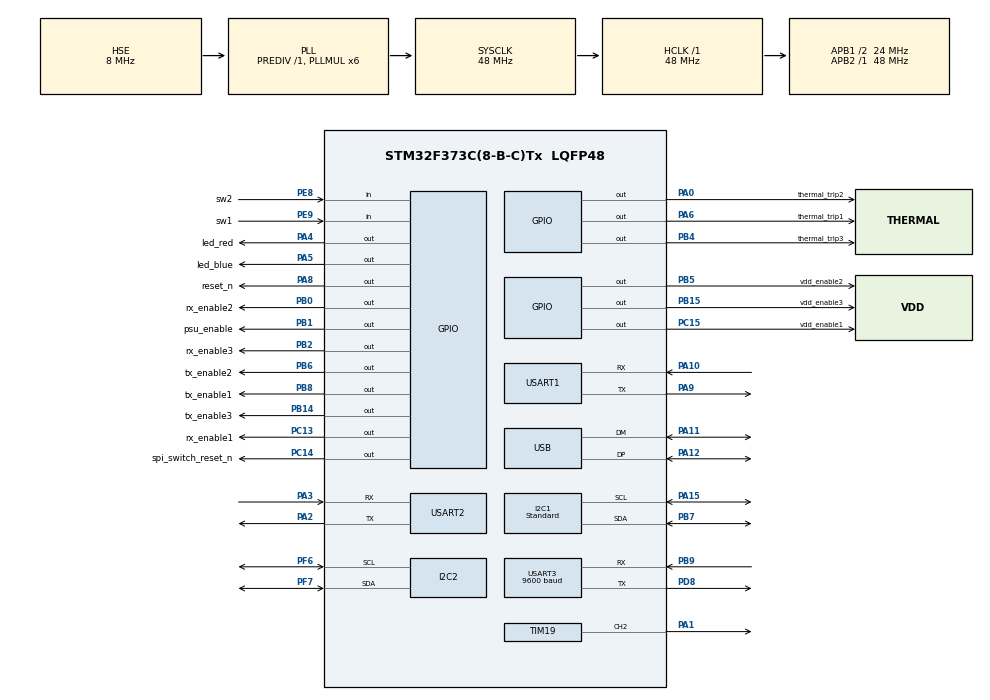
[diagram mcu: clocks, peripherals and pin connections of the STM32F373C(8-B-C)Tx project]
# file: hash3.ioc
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Dma.Request0=USART1_RX
Dma.Request1=USART1_TX
Dma.Request2=USART2_RX
Dma.Request3=USART2_TX
Dma.Request4=USART3_RX
Dma.Request5=USART3_TX
Dma.USART1_RX.0.Direction=DMA_PERIPH_TO_MEMORY
Dma.USART1_RX.0.Instance=DMA1_Channel5
Dma.USART1_RX.0.MemDataAlignment=DMA_MDATAALIGN_BYTE
Dma.USART1_RX.0.MemInc=DMA_MINC_ENABLE
Dma.USART1_RX.0.Mode=DMA_CIRCULAR
Dma.USART1_RX.0.PeriphDataAlignment=DMA_PDATAALIGN_BYTE
Dma.USART1_RX.0.PeriphInc=DMA_PINC_DISABLE
Dma.USART1_RX.0.Priority=DMA_PRIORITY_LOW
Dma.USART1_TX.1.Direction=DMA_MEMORY_TO_PERIPH
Dma.USART1_TX.1.Instance=DMA1_Channel4
Dma.USART1_TX.1.MemDataAlignment=DMA_MDATAALIGN_BYTE
Dma.USART1_TX.1.MemInc=DMA_MINC_ENABLE
Dma.USART1_TX.1.Mode=DMA_NORMAL
Dma.USART1_TX.1.PeriphDataAlignment=DMA_PDATAALIGN_BYTE
Dma.USART1_TX.1.PeriphInc=DMA_PINC_DISABLE
Dma.USART1_TX.1.Priority=DMA_PRIORITY_LOW
Dma.USART2_RX.2.Direction=DMA_PERIPH_TO_MEMORY
Dma.USART2_RX.2.Instance=DMA1_Channel6
Dma.USART2_RX.2.MemDataAlignment=DMA_MDATAALIGN_BYTE
Dma.USART2_RX.2.MemInc=DMA_MINC_ENABLE
Dma.USART2_RX.2.Mode=DMA_CIRCULAR
Dma.USART2_RX.2.PeriphDataAlignment=DMA_PDATAALIGN_BYTE
Dma.USART2_RX.2.PeriphInc=DMA_PINC_DISABLE
Dma.USART2_RX.2.Priority=DMA_PRIORITY_LOW
Dma.USART2_TX.3.Direction=DMA_MEMORY_TO_PERIPH
Dma.USART2_TX.3.Instance=DMA1_Channel7
Dma.USART2_TX.3.MemDataAlignment=DMA_MDATAALIGN_BYTE
Dma.USART2_TX.3.MemInc=DMA_MINC_ENABLE
Dma.USART2_TX.3.Mode=DMA_NORMAL
Dma.USART2_TX.3.PeriphDataAlignment=DMA_PDATAALIGN_BYTE
Dma.USART2_TX.3.PeriphInc=DMA_PINC_DISABLE
Dma.USART2_TX.3.Priority=DMA_PRIORITY_LOW
Dma.USART3_RX.4.Direction=DMA_PERIPH_TO_MEMORY
Dma.USART3_RX.4.Instance=DMA1_Channel3
Dma.USART3_RX.4.MemDataAlignment=DMA_MDATAALIGN_BYTE
Dma.USART3_RX.4.MemInc=DMA_MINC_ENABLE
Dma.USART3_RX.4.Mode=DMA_CIRCULAR
Dma.USART3_RX.4.PeriphDataAlignment=DMA_PDATAALIGN_BYTE
Dma.USART3_RX.4.PeriphInc=DMA_PINC_DISABLE
Dma.USART3_RX.4.Priority=DMA_PRIORITY_LOW
Dma.USART3_TX.5.Direction=DMA_MEMORY_TO_PERIPH
Dma.USART3_TX.5.Instance=DMA1_Channel2
Dma.USART3_TX.5.MemDataAlignment=DMA_MDATAALIGN_BYTE
Dma.USART3_TX.5.MemInc=DMA_MINC_ENABLE
Dma.USART3_TX.5.Mode=DMA_NORMAL
Dma.USART3_TX.5.PeriphDataAlignment=DMA_PDATAALIGN_BYTE
Dma.USART3_TX.5.PeriphInc=DMA_PINC_DISABLE
Dma.USART3_TX.5.Priority=DMA_PRIORITY_LOW
I2C1.I2C_Speed_Mode=I2C_Standard
Mcu.Family=STM32F3
Mcu.Name=STM32F373C(8-B-C)Tx
Mcu.Package=LQFP48
NVIC.DMA1_Channel2_IRQn=true\:0\:0\:false\:false\:true\:false\:true\:true
NVIC.DMA1_Channel3_IRQn=true\:0\:0\:false\:false\:true\:false\:true\:true
NVIC.DMA1_Channel4_IRQn=true\:0\:0\:false\:false\:true\:false\:true\:true
NVIC.DMA1_Channel5_IRQn=true\:0\:0\:false\:false\:true\:false\:true\:true
NVIC.DMA1_Channel6_IRQn=true\:0\:0\:false\:false\:true\:false\:true\:true
NVIC.DMA1_Channel7_IRQn=true\:0\:0\:false\:false\:true\:false\:true\:true
NVIC.PriorityGroup=NVIC_PRIORITYGROUP_4
NVIC.USART1_IRQn=true\:0\:0\:false\:false\:true\:true\:true\:true
NVIC.USART2_IRQn=true\:0\:0\:false\:false\:true\:true\:true\:true
NVIC.USART3_IRQn=true\:0\:0\:false\:false\:true\:true\:true\:true
NVIC.USB_LP_IRQn=true\:0\:0\:false\:false\:true\:false\:true\:true
PA0.GPIO_Label=thermal_trip2
PA0.Signal=GPIO_Output
PA1.Signal=S_TIM19_CH2
PA10.Mode=Asynchronous
PA10.Signal=USART1_RX
PA11.Mode=Device
PA11.Signal=USB_DM
PA12.Mode=Device
PA12.Signal=USB_DP
PA13.Mode=Trace_Asynchronous_SW
PA13.Signal=SYS_JTMS-SWDIO
PA14.Mode=Trace_Asynchronous_SW
PA14.Signal=SYS_JTCK-SWCLK
PA15.Mode=I2C
PA15.Signal=I2C1_SCL
PA2.Mode=Asynchronous
PA2.Signal=USART2_TX
PA3.Mode=Asynchronous
PA3.Signal=USART2_RX
PA4.GPIO_Label=led_red
PA4.Signal=GPIO_Output
PA5.GPIO_Label=led_blue
PA5.Signal=GPIO_Output
PA6.GPIO_Label=thermal_trip1
PA6.Signal=GPIO_Output
PA8.GPIO_Label=reset_n
PA8.Signal=GPIO_Output
PA9.Mode=Asynchronous
PA9.Signal=USART1_TX
PB0.GPIO_Label=rx_enable2
PB0.Signal=GPIO_Output
PB1.GPIO_Label=psu_enable
PB1.Signal=GPIO_Output
PB14.GPIO_Label=tx_enable3
PB14.Signal=GPIO_Output
PB15.GPIO_Label=vdd_enable3
PB15.Signal=GPIO_Output
PB2.GPIO_Label=rx_enable3
PB2.Signal=GPIO_Output
PB3.Mode=Trace_Asynchronous_SW
PB3.Signal=SYS_JTDO-TRACESWO
PB4.GPIO_Label=thermal_trip3
PB4.Signal=GPIO_Output
PB5.GPIO_Label=vdd_enable2
PB5.Signal=GPIO_Output
PB6.GPIO_Label=tx_enable2
PB6.Signal=GPIO_Output
PB7.Mode=I2C
PB7.Signal=I2C1_SDA
PB8.GPIO_Label=tx_enable1
PB8.Signal=GPIO_Output
PB9.Mode=Asynchronous
PB9.Signal=USART3_RX
PC13.GPIO_Label=rx_enable1
PC13.Signal=GPIO_Output
PC14-OSC32_IN.GPIO_Label=spi_switch_reset_n
PC14-OSC32_IN.Signal=GPIO_Output
PC15-OSC32_OUT.GPIO_Label=vdd_enable1
PC15-OSC32_OUT.Signal=GPIO_Output
PD8.Mode=Asynchronous
PD8.Signal=USART3_TX
PE8.GPIO_Label=sw2
PE8.GPIO_PuPd=GPIO_PULLUP
PE8.Signal=GPIO_Input
PE9.GPIO_Label=sw1
PE9.GPIO_PuPd=GPIO_PULLUP
PE9.Signal=GPIO_Input
PF0-OSC_IN.Mode=HSE-External-Oscillator
PF0-OSC_IN.Signal=RCC_OSC_IN
PF1-OSC_OUT.Mode=HSE-External-Oscillator
PF1-OSC_OUT.Signal=RCC_OSC_OUT
PF6.Mode=I2C
PF6.Signal=I2C2_SCL
PF7.Mode=I2C
PF7.Signal=I2C2_SDA
ProjectManager.HeapSize=0x800
ProjectManager.StackSize=0x800
ProjectManager.TargetToolchain=STM32CubeIDE
RCC.AHBFreq_Value=48000000
RCC.APB1CLKDivider=RCC_HCLK_DIV2
RCC.APB1Freq_Value=24000000
RCC.APB1TimFreq_Value=48000000
RCC.APB2Freq_Value=48000000
RCC.APB2TimFreq_Value=48000000
RCC.CortexFreq_Value=6000000
RCC.Cortex_Div=SYSTICK_CLKSOURCE_HCLK_DIV8
RCC.HCLKFreq_Value=48000000
RCC.HSE_VALUE=8000000
RCC.HSI_VALUE=8000000
RCC.LSE_VALUE=32768
RCC.PLLMUL=RCC_PLL_MUL6
RCC.SYSCLKFreq_VALUE=48000000
RCC.SYSCLKSource=RCC_SYSCLKSOURCE_PLLCLK
RCC.USBFreq_Value=48000000
RCC.Usart1ClockSelection=RCC_USART1CLKSOURCE_SYSCLK
RCC.Usart2ClockSelection=RCC_USART2CLKSOURCE_SYSCLK
RCC.Usart3ClockSelection=RCC_USART3CLKSOURCE_SYSCLK
SH.S_TIM19_CH2.0=TIM19_CH2,PWM Generation2 CH2
TIM19.AutoReloadPreload=TIM_AUTORELOAD_PRELOAD_ENABLE
TIM19.Channel-PWM\ Generation2\ CH2=TIM_CHANNEL_2
TIM19.Period=2880
TIM19.Pulse-PWM\ Generation2\ CH2=1
USART1.VirtualMode-Asynchronous=VM_ASYNC
USART2.VirtualMode-Asynchronous=VM_ASYNC
USART3.BaudRate=9600
USART3.VirtualMode-Asynchronous=VM_ASYNC
USB_DEVICE.CLASS_NAME_FS=CDC
USB_DEVICE.VirtualMode=Cdc
USB_DEVICE.VirtualModeFS=Cdc_FS
VP_TIM19_VS_ClockSourceINT.Mode=Internal
VP_USB_DEVICE_VS_USB_DEVICE_CDC_FS.Mode=CDC_FS
board=custom

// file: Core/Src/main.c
/* USER CODE BEGIN Header */
/**
  ******************************************************************************
  * @file           : main.c
  * @brief          : Main program body
  ******************************************************************************
  * @attention
  *
  * Copyright (c) 2023 STMicroelectronics.
  * All rights reserved.
  *
  * This software is licensed under terms that can be found in the LICENSE file
  * in the root directory of this software component.
  * If no LICENSE file comes with this software, it is provided AS-IS.
  *
  ******************************************************************************
  */
/* USER CODE END Header */
#include "main.h"
#include "usb_device.h"

I2C_HandleTypeDef hi2c1;
I2C_HandleTypeDef hi2c2;

TIM_HandleTypeDef htim19;

UART_HandleTypeDef huart1;
UART_HandleTypeDef huart2;
UART_HandleTypeDef huart3;
DMA_HandleTypeDef hdma_usart1_rx;
DMA_HandleTypeDef hdma_usart1_tx;
DMA_HandleTypeDef hdma_usart2_rx;
DMA_HandleTypeDef hdma_usart2_tx;
DMA_HandleTypeDef hdma_usart3_rx;
DMA_HandleTypeDef hdma_usart3_tx;

void SystemClock_Config(void);
static void MX_GPIO_Init(void);
static void MX_DMA_Init(void);
static void MX_USART1_UART_Init(void);
static void MX_USART2_UART_Init(void);
static void MX_USART3_UART_Init(void);
static void MX_I2C1_Init(void);
static void MX_I2C2_Init(void);
static void MX_TIM19_Init(void);

/* USER CODE BEGIN 0 */
void Init();
void Loop();

/* USER CODE END 0 */

int main(void)
{

  /* MCU Configuration--------------------------------------------------------*/

  /* Reset of all peripherals, Initializes the Flash interface and the Systick. */
  HAL_Init();

  /* Configure the system clock */
  SystemClock_Config();

  /* Initialize all configured peripherals */
  MX_GPIO_Init();
  MX_DMA_Init();
  MX_USART1_UART_Init();
  MX_USART2_UART_Init();
  MX_USART3_UART_Init();
  MX_I2C1_Init();
  MX_I2C2_Init();
  MX_USB_DEVICE_Init();
  MX_TIM19_Init();
  /* USER CODE BEGIN 2 */
  Init();

  /* USER CODE END 2 */

  /* Infinite loop */
  while (1)
  {

    /* USER CODE BEGIN 3 */
      Loop();
  }
  /* USER CODE END 3 */
}

void SystemClock_Config(void)
{
  RCC_OscInitTypeDef RCC_OscInitStruct = {0};
  RCC_ClkInitTypeDef RCC_ClkInitStruct = {0};
  RCC_PeriphCLKInitTypeDef PeriphClkInit = {0};

  /** Initializes the RCC Oscillators according to the specified parameters
  * in the RCC_OscInitTypeDef structure.
  */
  RCC_OscInitStruct.OscillatorType = RCC_OSCILLATORTYPE_HSI|RCC_OSCILLATORTYPE_HSE;
  RCC_OscInitStruct.HSEState = RCC_HSE_ON;
  RCC_OscInitStruct.HSEPredivValue = RCC_HSE_PREDIV_DIV1;
  RCC_OscInitStruct.HSIState = RCC_HSI_ON;
  RCC_OscInitStruct.HSICalibrationValue = RCC_HSICALIBRATION_DEFAULT;
  RCC_OscInitStruct.PLL.PLLState = RCC_PLL_ON;
  RCC_OscInitStruct.PLL.PLLSource = RCC_PLLSOURCE_HSE;
  RCC_OscInitStruct.PLL.PLLMUL = RCC_PLL_MUL6;
  if (HAL_RCC_OscConfig(&RCC_OscInitStruct) != HAL_OK)
  {
    Error_Handler();
  }

  /** Initializes the CPU, AHB and APB buses clocks
  */
  RCC_ClkInitStruct.ClockType = RCC_CLOCKTYPE_HCLK|RCC_CLOCKTYPE_SYSCLK
                              |RCC_CLOCKTYPE_PCLK1|RCC_CLOCKTYPE_PCLK2;
  RCC_ClkInitStruct.SYSCLKSource = RCC_SYSCLKSOURCE_PLLCLK;
  RCC_ClkInitStruct.AHBCLKDivider = RCC_SYSCLK_DIV1;
  RCC_ClkInitStruct.APB1CLKDivider = RCC_HCLK_DIV2;
  RCC_ClkInitStruct.APB2CLKDivider = RCC_HCLK_DIV1;

  if (HAL_RCC_ClockConfig(&RCC_ClkInitStruct, FLASH_LATENCY_1) != HAL_OK)
  {
    Error_Handler();
  }
  PeriphClkInit.PeriphClockSelection = RCC_PERIPHCLK_USB|RCC_PERIPHCLK_USART1
                              |RCC_PERIPHCLK_USART2|RCC_PERIPHCLK_USART3
                              |RCC_PERIPHCLK_I2C1|RCC_PERIPHCLK_I2C2;
  PeriphClkInit.Usart1ClockSelection = RCC_USART1CLKSOURCE_SYSCLK;
  PeriphClkInit.Usart2ClockSelection = RCC_USART2CLKSOURCE_SYSCLK;
  PeriphClkInit.Usart3ClockSelection = RCC_USART3CLKSOURCE_SYSCLK;
  PeriphClkInit.I2c1ClockSelection = RCC_I2C1CLKSOURCE_HSI;
  PeriphClkInit.I2c2ClockSelection = RCC_I2C2CLKSOURCE_HSI;
  PeriphClkInit.USBClockSelection = RCC_USBCLKSOURCE_PLL;
  if (HAL_RCCEx_PeriphCLKConfig(&PeriphClkInit) != HAL_OK)
  {
    Error_Handler();
  }
}

static void MX_I2C1_Init(void)
{

  hi2c1.Instance = I2C1;
  hi2c1.Init.Timing = 0x2000090E;
  hi2c1.Init.OwnAddress1 = 0;
  hi2c1.Init.AddressingMode = I2C_ADDRESSINGMODE_7BIT;
  hi2c1.Init.DualAddressMode = I2C_DUALADDRESS_DISABLE;
  hi2c1.Init.OwnAddress2 = 0;
  hi2c1.Init.OwnAddress2Masks = I2C_OA2_NOMASK;
  hi2c1.Init.GeneralCallMode = I2C_GENERALCALL_DISABLE;
  hi2c1.Init.NoStretchMode = I2C_NOSTRETCH_DISABLE;
  if (HAL_I2C_Init(&hi2c1) != HAL_OK)
  {
    Error_Handler();
  }

  /** Configure Analogue filter
  */
  if (HAL_I2CEx_ConfigAnalogFilter(&hi2c1, I2C_ANALOGFILTER_ENABLE) != HAL_OK)
  {
    Error_Handler();
  }

  /** Configure Digital filter
  */
  if (HAL_I2CEx_ConfigDigitalFilter(&hi2c1, 0) != HAL_OK)
  {
    Error_Handler();
  }

}

static void MX_I2C2_Init(void)
{

  hi2c2.Instance = I2C2;
  hi2c2.Init.Timing = 0x2000090E;
  hi2c2.Init.OwnAddress1 = 0;
  hi2c2.Init.AddressingMode = I2C_ADDRESSINGMODE_7BIT;
  hi2c2.Init.DualAddressMode = I2C_DUALADDRESS_DISABLE;
  hi2c2.Init.OwnAddress2 = 0;
  hi2c2.Init.OwnAddress2Masks = I2C_OA2_NOMASK;
  hi2c2.Init.GeneralCallMode = I2C_GENERALCALL_DISABLE;
  hi2c2.Init.NoStretchMode = I2C_NOSTRETCH_DISABLE;
  if (HAL_I2C_Init(&hi2c2) != HAL_OK)
  {
    Error_Handler();
  }

  /** Configure Analogue filter
  */
  if (HAL_I2CEx_ConfigAnalogFilter(&hi2c2, I2C_ANALOGFILTER_ENABLE) != HAL_OK)
  {
    Error_Handler();
  }

  /** Configure Digital filter
  */
  if (HAL_I2CEx_ConfigDigitalFilter(&hi2c2, 0) != HAL_OK)
  {
    Error_Handler();
  }

}

static void MX_TIM19_Init(void)
{

  TIM_ClockConfigTypeDef sClockSourceConfig = {0};
  TIM_MasterConfigTypeDef sMasterConfig = {0};
  TIM_OC_InitTypeDef sConfigOC = {0};

  htim19.Instance = TIM19;
  htim19.Init.Prescaler = 0;
  htim19.Init.CounterMode = TIM_COUNTERMODE_UP;
  htim19.Init.Period = 2880;
  htim19.Init.ClockDivision = TIM_CLOCKDIVISION_DIV1;
  htim19.Init.AutoReloadPreload = TIM_AUTORELOAD_PRELOAD_ENABLE;
  if (HAL_TIM_Base_Init(&htim19) != HAL_OK)
  {
    Error_Handler();
  }
  sClockSourceConfig.ClockSource = TIM_CLOCKSOURCE_INTERNAL;
  if (HAL_TIM_ConfigClockSource(&htim19, &sClockSourceConfig) != HAL_OK)
  {
    Error_Handler();
  }
  if (HAL_TIM_PWM_Init(&htim19) != HAL_OK)
  {
    Error_Handler();
  }
  sMasterConfig.MasterOutputTrigger = TIM_TRGO_RESET;
  sMasterConfig.MasterSlaveMode = TIM_MASTERSLAVEMODE_DISABLE;
  if (HAL_TIMEx_MasterConfigSynchronization(&htim19, &sMasterConfig) != HAL_OK)
  {
    Error_Handler();
  }
  sConfigOC.OCMode = TIM_OCMODE_PWM1;
  sConfigOC.Pulse = 1;
  sConfigOC.OCPolarity = TIM_OCPOLARITY_HIGH;
  sConfigOC.OCFastMode = TIM_OCFAST_DISABLE;
  if (HAL_TIM_PWM_ConfigChannel(&htim19, &sConfigOC, TIM_CHANNEL_2) != HAL_OK)
  {
    Error_Handler();
  }
  HAL_TIM_MspPostInit(&htim19);

}

static void MX_USART1_UART_Init(void)
{

  huart1.Instance = USART1;
  huart1.Init.BaudRate = 38400;
  huart1.Init.WordLength = UART_WORDLENGTH_8B;
  huart1.Init.StopBits = UART_STOPBITS_1;
  huart1.Init.Parity = UART_PARITY_NONE;
  huart1.Init.Mode = UART_MODE_TX_RX;
  huart1.Init.HwFlowCtl = UART_HWCONTROL_NONE;
  huart1.Init.OverSampling = UART_OVERSAMPLING_16;
  huart1.Init.OneBitSampling = UART_ONE_BIT_SAMPLE_DISABLE;
  huart1.AdvancedInit.AdvFeatureInit = UART_ADVFEATURE_NO_INIT;
  if (HAL_UART_Init(&huart1) != HAL_OK)
  {
    Error_Handler();
  }

}

static void MX_USART2_UART_Init(void)
{

  huart2.Instance = USART2;
  huart2.Init.BaudRate = 38400;
  huart2.Init.WordLength = UART_WORDLENGTH_8B;
  huart2.Init.StopBits = UART_STOPBITS_1;
  huart2.Init.Parity = UART_PARITY_NONE;
  huart2.Init.Mode = UART_MODE_TX_RX;
  huart2.Init.HwFlowCtl = UART_HWCONTROL_NONE;
  huart2.Init.OverSampling = UART_OVERSAMPLING_16;
  huart2.Init.OneBitSampling = UART_ONE_BIT_SAMPLE_DISABLE;
  huart2.AdvancedInit.AdvFeatureInit = UART_ADVFEATURE_NO_INIT;
  if (HAL_UART_Init(&huart2) != HAL_OK)
  {
    Error_Handler();
  }

}

static void MX_USART3_UART_Init(void)
{

  huart3.Instance = USART3;
  huart3.Init.BaudRate = 9600;
  huart3.Init.WordLength = UART_WORDLENGTH_8B;
  huart3.Init.StopBits = UART_STOPBITS_1;
  huart3.Init.Parity = UART_PARITY_NONE;
  huart3.Init.Mode = UART_MODE_TX_RX;
  huart3.Init.HwFlowCtl = UART_HWCONTROL_NONE;
  huart3.Init.OverSampling = UART_OVERSAMPLING_16;
  huart3.Init.OneBitSampling = UART_ONE_BIT_SAMPLE_DISABLE;
  huart3.AdvancedInit.AdvFeatureInit = UART_ADVFEATURE_NO_INIT;
  if (HAL_UART_Init(&huart3) != HAL_OK)
  {
    Error_Handler();
  }

}

static void MX_DMA_Init(void)
{

  /* DMA controller clock enable */
  __HAL_RCC_DMA1_CLK_ENABLE();

  /* DMA interrupt init */
  /* DMA1_Channel2_IRQn interrupt configuration */
  HAL_NVIC_SetPriority(DMA1_Channel2_IRQn, 0, 0);
  HAL_NVIC_EnableIRQ(DMA1_Channel2_IRQn);
  /* DMA1_Channel3_IRQn interrupt configuration */
  HAL_NVIC_SetPriority(DMA1_Channel3_IRQn, 0, 0);
  HAL_NVIC_EnableIRQ(DMA1_Channel3_IRQn);
  /* DMA1_Channel4_IRQn interrupt configuration */
  HAL_NVIC_SetPriority(DMA1_Channel4_IRQn, 0, 0);
  HAL_NVIC_EnableIRQ(DMA1_Channel4_IRQn);
  /* DMA1_Channel5_IRQn interrupt configuration */
  HAL_NVIC_SetPriority(DMA1_Channel5_IRQn, 0, 0);
  HAL_NVIC_EnableIRQ(DMA1_Channel5_IRQn);
  /* DMA1_Channel6_IRQn interrupt configuration */
  HAL_NVIC_SetPriority(DMA1_Channel6_IRQn, 0, 0);
  HAL_NVIC_EnableIRQ(DMA1_Channel6_IRQn);
  /* DMA1_Channel7_IRQn interrupt configuration */
  HAL_NVIC_SetPriority(DMA1_Channel7_IRQn, 0, 0);
  HAL_NVIC_EnableIRQ(DMA1_Channel7_IRQn);

}

static void MX_GPIO_Init(void)
{
  GPIO_InitTypeDef GPIO_InitStruct = {0};

  /* GPIO Ports Clock Enable */
  __HAL_RCC_GPIOC_CLK_ENABLE();
  __HAL_RCC_GPIOF_CLK_ENABLE();
  __HAL_RCC_GPIOA_CLK_ENABLE();
  __HAL_RCC_GPIOB_CLK_ENABLE();
  __HAL_RCC_GPIOE_CLK_ENABLE();
  __HAL_RCC_GPIOD_CLK_ENABLE();

  /*Configure GPIO pin Output Level */
  HAL_GPIO_WritePin(GPIOC, rx_enable1_Pin|spi_switch_reset_n_Pin|vdd_enable1_Pin, GPIO_PIN_RESET);

  /*Configure GPIO pin Output Level */
  HAL_GPIO_WritePin(GPIOA, thermal_trip2_Pin|led_red_Pin|led_blue_Pin|thermal_trip1_Pin
                          |reset_n_Pin, GPIO_PIN_RESET);

  /*Configure GPIO pin Output Level */
  HAL_GPIO_WritePin(GPIOB, rx_enable2_Pin|psu_enable_Pin|rx_enable3_Pin|tx_enable3_Pin
                          |vdd_enable3_Pin|thermal_trip3_Pin|vdd_enable2_Pin|tx_enable2_Pin
                          |tx_enable1_Pin, GPIO_PIN_RESET);

  /*Configure GPIO pins : rx_enable1_Pin spi_switch_reset_n_Pin vdd_enable1_Pin */
  GPIO_InitStruct.Pin = rx_enable1_Pin|spi_switch_reset_n_Pin|vdd_enable1_Pin;
  GPIO_InitStruct.Mode = GPIO_MODE_OUTPUT_PP;
  GPIO_InitStruct.Pull = GPIO_NOPULL;
  GPIO_InitStruct.Speed = GPIO_SPEED_FREQ_LOW;
  HAL_GPIO_Init(GPIOC, &GPIO_InitStruct);

  /*Configure GPIO pins : thermal_trip2_Pin led_red_Pin led_blue_Pin thermal_trip1_Pin
                           reset_n_Pin */
  GPIO_InitStruct.Pin = thermal_trip2_Pin|led_red_Pin|led_blue_Pin|thermal_trip1_Pin
                          |reset_n_Pin;
  GPIO_InitStruct.Mode = GPIO_MODE_OUTPUT_PP;
  GPIO_InitStruct.Pull = GPIO_NOPULL;
  GPIO_InitStruct.Speed = GPIO_SPEED_FREQ_LOW;
  HAL_GPIO_Init(GPIOA, &GPIO_InitStruct);

  /*Configure GPIO pins : rx_enable2_Pin psu_enable_Pin rx_enable3_Pin tx_enable3_Pin
                           vdd_enable3_Pin thermal_trip3_Pin vdd_enable2_Pin tx_enable2_Pin
                           tx_enable1_Pin */
  GPIO_InitStruct.Pin = rx_enable2_Pin|psu_enable_Pin|rx_enable3_Pin|tx_enable3_Pin
                          |vdd_enable3_Pin|thermal_trip3_Pin|vdd_enable2_Pin|tx_enable2_Pin
                          |tx_enable1_Pin;
  GPIO_InitStruct.Mode = GPIO_MODE_OUTPUT_PP;
  GPIO_InitStruct.Pull = GPIO_NOPULL;
  GPIO_InitStruct.Speed = GPIO_SPEED_FREQ_LOW;
  HAL_GPIO_Init(GPIOB, &GPIO_InitStruct);

  /*Configure GPIO pins : sw2_Pin sw1_Pin */
  GPIO_InitStruct.Pin = sw2_Pin|sw1_Pin;
  GPIO_InitStruct.Mode = GPIO_MODE_INPUT;
  GPIO_InitStruct.Pull = GPIO_PULLUP;
  HAL_GPIO_Init(GPIOE, &GPIO_InitStruct);

}

void Error_Handler(void)
{
  __disable_irq();
  while (1)
  {
  }
}
